# SN32F700 register map
Vendor: SONiX Technology Co., Ltd.; Series: SN32F700; File version: 1.9
CPU: CM0 r0p0, little endian, no MPU, no FPU, 2 interrupt priority bits
Registers are 32-bit, read-write, reset 0x0 unless marked. A register's access mark holds for its fields unless they carry their own. Offsets are from the block's base; [hi:lo] are bit positions; {n}, {i} and the like mark numbered series.

## SN_USART0 — USART0
Base 0x40016000
Same registers: SN_USART1 0x40056000
0x00 RB ro — Offset:0x00 USARTn Receiver Buffer Register
  [7:0] RB — The oldest received byte in USART RX FIFO
0x00 TH (alternate view of RB) — Offset:0x00 USARTn Transmit Holding Register
  [7:0] TH wo — The oldest byte to be transmitted in USART TX FIFO when transmitter is available
0x00 DLL reset 0x1 (alternate view of RB) — Offset:0x00 USARTn Divisor Latch LSB Register
  [7:0] DLL — DLL and DLM register determines the baud rate of USARTn
0x04 DLM — Offset:0x04 USARTn Divisor Latch MSB Register
  [7:0] DLM — DLL and DLM register determines the baud rate of USARTn
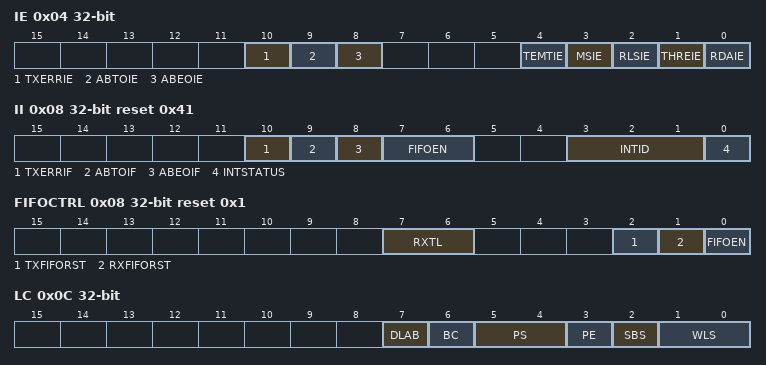
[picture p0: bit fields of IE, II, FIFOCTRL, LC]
0x04 IE (alternate view of DLM) — Offset:0x04 USARTn Interrupt Enable Register
  [10] TXERRIE — TXERR interrupt enable
    0=Disable TXERR interrupt; 1=Enable TXERR interrupt
  [9] ABTOIE — ABT0 interrupt enable
    0=Disable ABTO interrupt; 1=Enable ABTO interrupt
  [8] ABEOIE — ABE0 interrupt enable
    0=Disable ABEO interrupt; 1=Enable ABEO interrupt
  [4] TEMTIE — TEMT interrupt enable
    0=Disable TEMT interrupt; 1=Enable TEMT interrupt
  [3] MSIE — MS interrupt enable
    0=Disable MS interrupt; 1=Enable MS interrupt
  [2] RLSIE — RLS interrupt enable
    0=Disable RLS interrupt; 1=Enable RLS interrupt
  [1] THREIE — THRE interrupt enable
    0=Disable THRE interrupt; 1=Enable THRE interrupt
  [0] RDAIE — RDA interrupt enable
    0=Disable RDA interrupt; 1=Enable RDA interrupt
0x08 II ro reset 0x41 — Offset:0x08 USARTn Interrupt Identification Register
  [10] TXERRIF — TXERR interrupt flag
    0=No error (TXERR has not occurred); 1=TX error (TXERR has occurred and interrupt is enabled)
  [9] ABTOIF — ABTO interrupt flag
    0=Not Time-out (Auto-baud has not timed out); 1=Time-out (Auto-baud has timed out and interrupt is enabled)
  [8] ABEOIF — ABEO interrupt flag
    0=Not end (Auto-baud has not finished); 1=End (Auto-baud has finished and interrupt is enabled)
  [7:6] FIFOEN — Equal to FIFOEN bits in USARTn_FIFOCTRL register
  [3:1] INTID — Interrupt ID of RX FIFO
    0=Modem status; 1=3a (THRE interrupt); 2=2a (RDA (Receive Data Available)); 3=RLS (Receive Line Status); 6=2b (CTI (Character Time-out Indicator)); 7=3b (TEMT interrupt)
  [0] INTSTATUS — Interrupt status
    0=Pending (As least 1 interrupt is pending); 1=No interrupt
0x08 FIFOCTRL wo reset 0x1 — Offset:0x08 USARTn FIFO Control Register
  [7:6] RXTL — RX trigger level
    0=Trigger level 0 (1 character); 1=Trigger level 1 (4 character); 2=Trigger level 2 (8 character); 3=Trigger level 3 (14 character)
  [2] TXFIFORST — TX FIFO reset
    0=No impact; 1=Reset the pointer logic in TX FIFO
  [1] RXFIFORST — RX FIFO reset
    0=No impact; 1=Reset the pointer logic in RX FIFO
  [0] FIFOEN — FIFO enable
    0=No effect; 1=Enable FIFO
0x0C LC (reset mask 0xF) — Offset:0x0C USARTn Line Control Register
  [7] DLAB — Divisor Latch access
    0=Disable access to Divisor Latch; 1=Enable access to Divisor Latch
  [6] BC — Break control
    0=Disable break transmission; 1=Enable break transmission
  [5:4] PS — Parity selection
    0=Odd parity; 1=Even parity; 2=Forced 1 sticky parity; 3=Forced 0 sticky parity
  [3] PE — Parity enable
    0=Disable parity generation and checking; 1=Enable parity generation and checking
  [2] SBS — Stop bit selection
    0=1 stop bit; 1=2 stop bit (1.5 stop bit if WLS=0)
  [1:0] WLS — Word length selection
    {v}={v+5}-bit character (v=0..3)
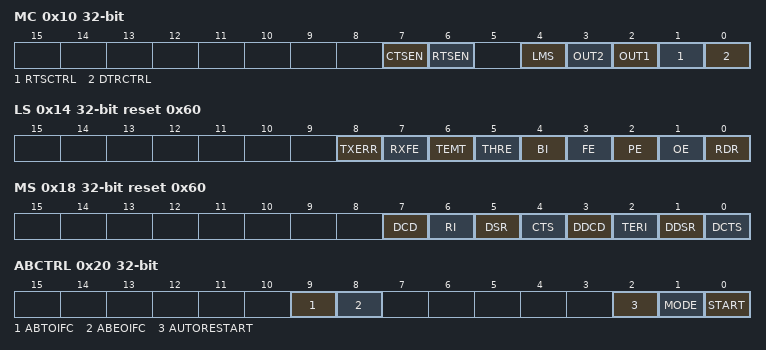
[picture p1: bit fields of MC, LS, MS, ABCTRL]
0x10 MC (reset mask 0xF) — Offset:0x10 USARTn Modem Control Register
  [7] CTSEN — CTS enable
    0=Disable auto-CTS flow control; 1=Enable auto-CTS flow control
  [6] RTSEN — RTS enable
    0=Disable auto-RTS flow control; 1=Enable auto-RTS flow control
  [4] LMS — Modem loopback mode enable
    0=Disable loopback mode; 1=Enable loopback mode
  [3] OUT2 — Control OUT2 internal signal in loopback mode.
  [2] OUT1 — Control OUT1 internal signal in loopback mode.
  [1] RTSCTRL — Source from modem output (RTS) pin
  [0] DTRCTRL — Source from modem output (DTR) pin
0x14 LS ro reset 0x60 — Offset:0x14 USARTn Line Status Register
  [8] TXERR — TX error flag
    0=No TX error (USARTn_RB contains no USART RX errors); 1=TX FIFO error (Smart card has NACKed a transmitted character)
  [7] RXFE — Receiver FIFO error flag
    0=No RX FIFO error (USARTn_RB contains no USART RX errors); 1=RX FIFO error (USARTn_RB contains at least 1 USART RX error)
  [6] TEMT — Transmitter empty flag
    0=Not empty (THR and/or TSR contains valid data); 1=Empty (THR and TSR are both empty)
  [5] THRE — THR empty flag
    0=Not empty (THR contains valid data); 1=Empty (THR (TX FIFO) is empty)
  [4] BI — Break interrupt flag
    0=No break interrupt; 1=Break interrupt status is active
  [3] FE — Framing error flag
    0=No framing error; 1=Framing error status is active
  [2] PE — Parity error flag
    0=No parity error; 1=Parity error status is active
  [1] OE — Overrun error flag
    0=No overrun error; 1=Overrun error status is active
  [0] RDR — Receiver data ready flag
    0=Not ready (USARTn_RB FIFO is empty); 1=Ready (USARTn_RB FIFO contains valid data)
0x18 MS ro reset 0x60 — Offset:0x18 USARTn Modem Status Register
  [7] DCD — Complement of DCD pin input signal
  [6] RI — Complement of RI pin input signal
  [5] DSR — Complement of DSR pin input signal
  [4] CTS — Complement of CTS pin input signal
  [3] DDCD — Delta DCD
    0=No change detected on DCD pin; 1=State changes detected on DCD pin
  [2] TERI — Trailing edge RI
    0=No change detected on RI pin; 1=State changes (Low-to-high transition detected on RI pin)
  [1] DDSR — Delta DSR
    0=No change detected on DSR pin; 1=State changes detected on DSR pin
  [0] DCTS — Delta CTS
    0=No change detected on modem input CTS pin; 1=State changes detected on modem input CTS pin
0x1C SP — Offset:0x1C USARTn Scratch Pad Register
  [7:0] PAD — Pad informaton
0x20 ABCTRL — Offset:0x20 USARTn Auto-baud Control Register
  [9] ABTOIFC wo — Clear ABTOIF flag
    0=No effect; 1=Clear ABTOIF bit
  [8] ABEOIFC wo — Clear ABEOIF flag
    0=No effect; 1=Clear ABEOIF bit
  [2] AUTORESTART — Restart mode selection
    0=No restart; 1=Restart (Auto restart in case of timeout)
  [1] MODE — Auto-baud mode selection
    0=Mode 0 (Auto-baud mode 0); 1=Mode 1 (Auto-baud mode 1)
  [0] START — Auto-baud run bit
    0=Stop (Auto-baud is not running); 1=Start (Auto-baud ids running)
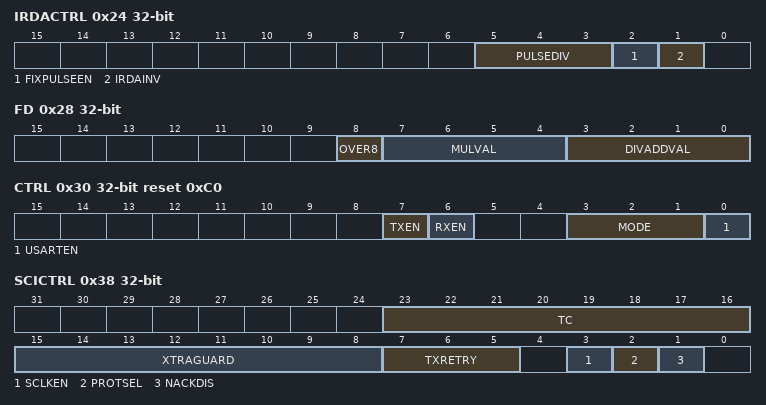
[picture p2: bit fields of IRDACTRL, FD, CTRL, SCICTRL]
0x24 IRDACTRL — Offset:0x24 USARTn IrDA Control Register
  [5:3] PULSEDIV — Pulse width selection
    0=000b (2 * TPCLK); 1=001b (4 * TPCLK); 2=010b (8 * TPCLK); 3=011b (16 * TPCLK); 4=100b (32 * TPCLK); 5=101b (64 * TPCLK); 6=110b (128 * TPCLK); 7=111b (256 * TPCLK)
  [2] FIXPULSEEN — IrDA fix pulse width mode enable
    0=Disable (Pulse width = 3 / (Oversampling * Baud rate)); 1=Enable (Pulse width is set by PULSEDIV bits)
  [1] IRDAINV — IrDA serial input inverter
    0=No inverted (IrDA serial input is not inverted); 1=Inverted (IrDA serial input is inverted)
0x28 FD — Offset:0x28 USARTn Fractional Divider Register
  [8] OVER8 — Oversampling value
    0=Oversampling by 16; 1=Oversampling by 8
  [7:4] MULVAL — Baud rate generation prescaler multiplier value
    0=0000b (Baud rate prescaler multiplier value is 1); 1=0001b (Baud rate prescaler multiplier value is 2); 2=0010b (Baud rate prescaler multiplier value is 3); 3=0011b (Baud rate prescaler multiplier value is 4); 4=0100b (Baud rate prescaler multiplier value is 5); 5=0101b (Baud rate prescaler multiplier value is 6); 6=0110b (Baud rate prescaler multiplier value is 7); 7=0111b (Baud rate prescaler multiplier value is 8); 8=1000b (Baud rate prescaler multiplier value is 9); 9=1001b (Baud rate prescaler multiplier value is 10); 10=1010b (Baud rate prescaler multiplier value is 11); 11=1011b (Baud rate prescaler multiplier value is 12); 12=1100b (Baud rate prescaler multiplier value is 13); 13=1101b (Baud rate prescaler multiplier value is 14); 14=1110b (Baud rate prescaler multiplier value is 15); 15=1111b (Baud rate prescaler multiplier value is 16)
  [3:0] DIVADDVAL — Baud rate generation prescaler divisor value
0x30 CTRL reset 0xC0 — Offset:0x30 USARTn Control Register
  [7] TXEN — TX enable
    0=Disable TX; 1=Enable TX
  [6] RXEN — RX enable
    0=Disable RX; 1=Enable RX
  [3:1] MODE — USART mode
    0=UART (UART mode); 1=Modem control mode; 2=IrDA mode; 3=Smart card mode; 4=Synchronous mode; 5=RS-485 (RS-485 mode)
  [0] USARTEN — USART enable
    0=Disable USART; 1=Enable USART
0x34 HDEN — Offset:0x34 USARTn Control Register
  [0] HDEN — Half-duplex mode enable
    0=Disable half-duplex mode; 1=Enable half-duplex mode
0x38 SCICTRL — Offset:0x38 USARTn Smartcard Interface Control Register
  [23:16] TC — Count for SCLK clock cycle
  [15:8] XTRAGUARD — Extra guard time
  [7:5] TXRETRY — Maximal number of retransmissions that USART will attempt
  [3] SCLKEN — SCLK enable
    0=Disable SCLK; 1=Enable SCLK
  [2] PROTSEL — ISO7816-3 protocol selection
    0=T=0; 1=T=1
  [1] NACKDIS — NACK response disable
    0=Disable NACK response; 1=Enable NACK response
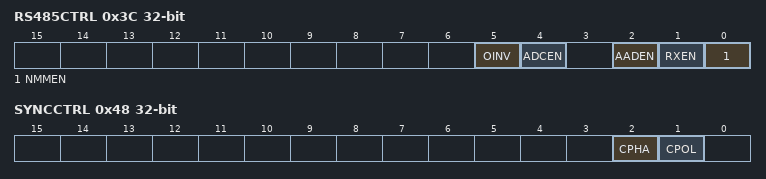
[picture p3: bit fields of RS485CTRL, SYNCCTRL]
0x3C RS485CTRL — Offset:0x3C USARTn RS485 Control Register
  [5] OINV — Polarity control
    0=Disable (The direction control pin will be driven to logic 0 when the transmitter has data to be sent, and be driven to logic 1 after the last bit of data has been transmitted); 1=Enable (The direction control pin will be driven to logic 1 when the transmitter has data to be sent, and be driven to logic 0 after the last bit of data has been transmitted)
  [4] ADCEN — Auto direction control enable
    0=Disable ADC; 1=Enable ADC
  [2] AADEN — Auto address detect enable
    0=Disable AAD; 1=Enable AAD
  [1] RXEN — RS-485 receiver enable
    0=Disable RS-485 receiver; 1=Enable RS-485 receiver
  [0] NMMEN — RS-485 normal multidrop mode enable
    0=Disable NMM; 1=Enable NMM
0x40 RS485ADRMATCH — Offset:0x40 USARTn RS485 Address Match Register
  [7:0] MATCH — RS-485 address value to be matched
0x44 RS485DLYV — Offset:0x44 USARTn RS485 Delay Value Register
  [7:0] DLY — RTS delay value
0x48 SYNCCTRL — Offset:0x48 USARTn Synchronous Mode Control Register
  [2] CPHA — Clock phase for edge sampling
    0=Rising (Sample on the rising edge of SCLK); 1=Falling (Sample on the falling edge of SCLK)
  [1] CPOL — Clock polarity selection
    0=Low (SCLK idles at low level); 1=High (SCLK idles at high level)
